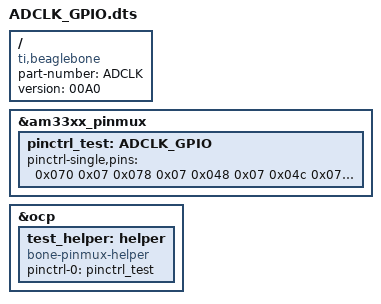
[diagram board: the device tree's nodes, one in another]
/*
 * adclock -  a program for driving an analog time display on the Beaglebone
 * 
 * The MIT License (MIT)
 *
 * Copyright (c) 2014  Michael J. Wouters
 *
 * Permission is hereby granted, free of charge, to any person obtaining a copy
 * of this software and associated documentation files (the "Software"), to deal
 * in the Software without restriction, including without limitation the rights
 * to use, copy, modify, merge, publish, distribute, sublicense, and/or sell
 * copies of the Software, and to permit persons to whom the Software is
 * furnished to do so, subject to the following conditions:
 *
 * The above copyright notice and this permission notice shall be included in
 * all copies or substantial portions of the Software.

 * THE SOFTWARE IS PROVIDED "AS IS", WITHOUT WARRANTY OF ANY KIND, EXPRESS OR
 * IMPLIED, INCLUDING BUT NOT LIMITED TO THE WARRANTIES OF MERCHANTABILITY,
 * FITNESS FOR A PARTICULAR PURPOSE AND NONINFRINGEMENT. IN NO EVENT SHALL THE
 * AUTHORS OR COPYRIGHT HOLDERS BE LIABLE FOR ANY CLAIM, DAMAGES OR OTHER
 * LIABILITY, WHETHER IN AN ACTION OF CONTRACT, TORT OR OTHERWISE, ARISING FROM,
 * OUT OF OR IN CONNECTION WITH THE SOFTWARE OR THE USE OR OTHER DEALINGS IN
 * THE SOFTWARE.
 */

/dts-v1/;
/plugin/;

/{
	compatible = "ti,beaglebone", "ti,beaglebone-black";
	part-number = "ADCLK";
	version = "00A0";

	fragment@0 {
		target = <&am33xx_pinmux>;
            
		__overlay__ {
			pinctrl_test: ADCLK_GPIO {
				pinctrl-single,pins = <

				0x070 0x07  /* P9_11 GPIO 30  */ /* Note: a hack because P9_12 is dead on my BB */
				0x078 0x07  /* P9_12 60   */ 
				0x048 0x07  /* P9_14 50  */
				0x04c 0x07  /* P9_16 51  */

				0x184 0x07  /* P9_24 15  */
				0x180 0x07  /* P9_26 14  */
				0x1a4 0x07  /* P9_27 115  */

				0x154 0x07  /* P9_21 3  */
				0x150 0x07  /* P9_22 2  */
				0x044 0x07  /* P9_23 49 */

				>;
			};
		};
	};

	fragment@1 {
		target = <&ocp>;
		__overlay__ {
			test_helper: helper {
				compatible = "bone-pinmux-helper";
				pinctrl-names = "default";
				pinctrl-0 = <&pinctrl_test>;
				status = "okay";
			};
		};
	};
};
